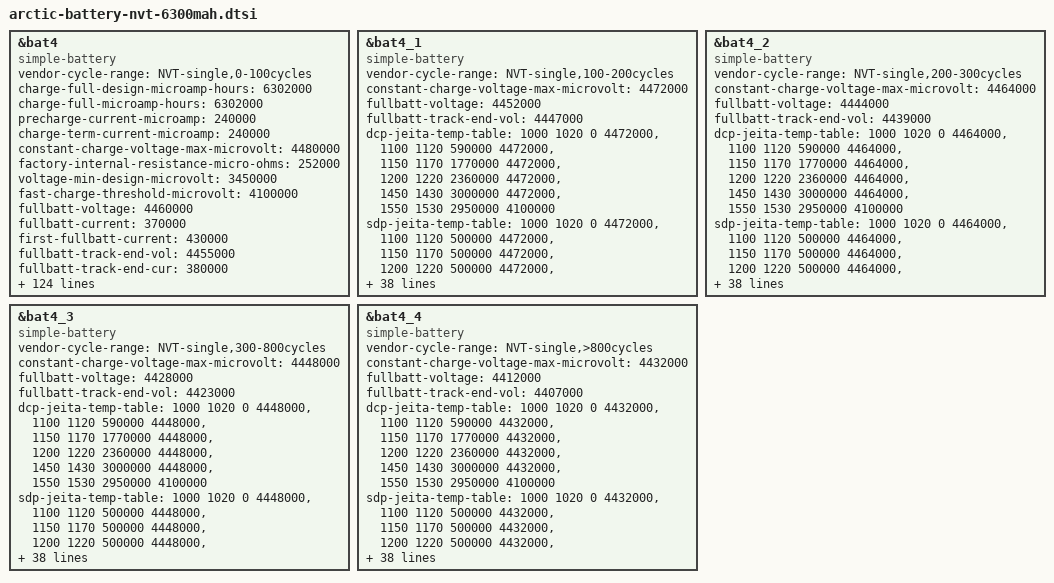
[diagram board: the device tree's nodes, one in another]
/* NVT-single aging 0--100 */
&bat4 {
	compatible = "simple-battery";
	status = "okay";
	vendor-cycle-range = "NVT-single,0-100cycles";
	charge-full-design-microamp-hours = <6302000>;
	charge-full-microamp-hours = <6302000>;
	precharge-current-microamp = <240000>;
	charge-term-current-microamp = <240000>;
	constant-charge-voltage-max-microvolt = <4480000>;
	factory-internal-resistance-micro-ohms = <252000>;
	voltage-min-design-microvolt = <3450000>;

	fast-charge-threshold-microvolt = <4100000>;
	fullbatt-voltage = <4460000>;
	fullbatt-current = <370000>;
	first-fullbatt-current = <430000>;
	fullbatt-track-end-vol = <4455000>;
	fullbatt-track-end-cur = <380000>;
	first-calib-voltage = <3580000>;
	first-calib-capacity = <50>;
	batt-ovp-threshold-microvolt = <4750000>;
	shutdown-voltage = <3150000>; //软件UVLO关机电压

	voltage-temp-table = <1119814 800>, <1007626 850>, <897107 900>,
				<791150 950>, <692012 1000>, <601214 1050>,
				<519546 1100>, <447188 1150>, <383853 1200>,
				<328947 1250>, <281696 1300>, <241249 1350>,
				<206756 1400>, <177412 1450>, <152480 1500>,
				<131307 1550>, <113324 1600>, <98032 1650>;

	temp-advance-fullcap-table = <50 100>, <25 100>, <10 100>, <0 100>,
		<(-10) 100>, <(-20) 100>;

	bcl-vbat-thres-celsius = <(-10)>, <0>, <10>, <25>, <45>;
	bcl-vbat-h-thres-0 = <3500>, <3400>;
	bcl-vbat-l-thres-0 = <3300>, <3200>;
	bcl-vbat-h-thres-1 = <3500>, <3400>;
	bcl-vbat-l-thres-1 = <3300>, <3200>;
	bcl-vbat-h-thres-2 = <3500>, <3400>;
	bcl-vbat-l-thres-2 = <3300>, <3200>;
	bcl-vbat-h-thres-3 = <3500>, <3400>;
	bcl-vbat-l-thres-3 = <3300>, <3200>;
	bcl-vbat-h-thres-4 = <3500>, <3400>;
	bcl-vbat-l-thres-4 = <3300>, <3200>;

	charge-sdp-current-microamp = <500000 500000>;
	charge-dcp-current-microamp = <2940000 1500000>;
	charge-cdp-current-microamp = <900000 900000>;
	charge-unknown-current-microamp = <1000000 1000000>;
	charge-fchg-current-microamp = <3000000 2000000>;
	charge-flash-current-microamp = <4900000 2700000>;
	charge-wl-bpp-current-microamp = <1000000 1000000>;
	charge-wl-epp-current-microamp = <2000000 1000000>;

	cap-calib-energy-density-ocv-table = <3400000 3690000>, <3895000 4480000>;

	dcp-jeita-temp-table = <1000 1020 0 4480000>, <1100 1120 590000 4480000>,
		<1150 1170 1770000 4480000>, <1200 1220 2360000 4480000>,
		<1450 1430 3000000 4480000>, <1550 1530 2950000 4100000>;
	sdp-jeita-temp-table = <1000 1020 0 4480000>, <1100 1120 500000 4480000>,
		<1150 1170 500000 4480000>, <1200 1220 500000 4480000>,
		<1450 1430 500000 4480000>, <1550 1530 500000 4100000>;
	cdp-jeita-temp-table = <1000 1020 0 4480000>, <1100 1120 590000 4480000>,
		<1150 1170 900000 4480000>, <1200 1220 900000 4480000>,
		<1450 1430 900000 4480000>, <1550 1530 900000 4100000>;
	unknown-jeita-temp-table = <1000 1020 0 4480000>, <1100 1120 590000 4480000>,
		<1150 1170 1000000 4480000>, <1200 1220 1000000 4480000>,
		<1450 1430 1000000 4480000>, <1550 1530 1000000 4100000>;
	fchg-jeita-temp-table = <1000 1020 0 4480000>, <1100 1120 590000 4480000>,
		<1150 1170 1770000 4480000>, <1200 1220 2360000 4480000>,
		<1450 1430 3000000 4480000>, <1550 1530 2950000 4100000>;
	flash-jeita-temp-table = <1000 1020 0 4480000>, <1100 1120 590000 4480000>,
		<1150 1170 1770000 4480000>, <1200 1220 2360000 4480000>,
		<1450 1430 3000000 4480000>, <1550 1530 2950000 4100000>;
	wl-bpp-jeita-temp-table = <1000 1020 0 4480000>, <1100 1120 500000 4480000>,
		<1150 1170 500000 4480000>, <1200 1220 500000 4480000>,
		<1450 1430 1000000 4480000>, <1550 1530 500000 4100000>;
	wl-epp-jeita-temp-table = <1000 1020 0 4480000>, <1100 1120 500000 4480000>,
		<1150 1170 500000 4480000>, <1200 1220 500000 4480000>,
		<1450 1430 2000000 4480000>, <1550 1530 500000 4100000>;


	bat-temp = <(-20)>, <(-10)>, <0>, <10>, <25>, <45>;

	/* temp-fcc */
	temp-fcc-fcc = <5744000>, <5938000>, <6229000>, <6271000>, <6302000>, <6250000>;

	/* temp-hc */
	temp-hc-hc = <20>, <20>, <20>, <10>, <10>, <10>;
	/* temp-zero-point-voltage */
	temp-zpvol-zpvol = <3430000>, <3430000>, <3430000>, <3450000>, <3450000>, <3450000>;
	/* temp-abs-zero-point-voltage */
	temp-abs-zpvol-zpvol = <3425000>, <3425000>, <3425000>, <3445000>, <3445000>, <3445000>;
	/* temp-bat-voltage */
	temp-batvol-batvol = <3570000>, <3570000>, <3570000>, <3580000>, <3580000>, <3580000>;

	/* cap-temp-ocv */
	cap-temp-ocv-cap = <100>, <99>, <98>, <97>, <96>, <95>, <94>, <93>, <92>, <91>, <90>,
			<89>, <88>, <87>, <86>, <85>, <84>, <83>, <82>, <81>, <80>,
			<79>, <78>, <77>, <76>, <75>, <74>, <73>, <72>, <71>, <70>,
			<69>, <68>, <67>, <66>, <65>, <64>, <63>, <62>, <61>, <60>,
			<59>, <58>, <57>, <56>, <55>, <54>, <53>, <52>, <51>, <50>,
			<49>, <48>, <47>, <46>, <45>, <44>, <43>, <42>, <41>, <40>,
			<39>, <38>, <37>, <36>, <35>, <34>, <33>, <32>, <31>, <30>,
			<29>, <28>, <27>, <26>, <25>, <24>, <23>, <22>, <21>, <20>,
			<19>, <18>, <17>, <16>, <15>, <14>, <13>, <12>, <11>, <10>,
			<9>, <8>, <7>, <6>, <5>, <4>, <3>, <2>, <1>, <0>;
	cap-temp-ocv-ocv = <
			/* -20 celsius */
			4431000 4394000 4370000 4350000 4333000 4318000 4302000 4288000 4275000 4262000
			4248000 4236000 4224000 4211000 4199000 4188000 4176000 4166000 4156000 4145000
			4135000 4125000 4116000 4106000 4097000 4088000 4078000 4070000 4060000 4051000
			4042000 4033000 4024000 4015000 4006000 3997000 3988000 3979000 3970000 3960000
			3952000 3943000 3934000 3926000 3917000 3908000 3900000 3892000 3884000 3877000
			3870000 3862000 3856000 3850000 3844000 3838000 3832000 3827000 3822000 3818000
			3813000 3809000 3806000 3802000 3799000 3796000 3794000 3792000 3789000 3787000
			3785000 3783000 3780000 3778000 3776000 3774000 3770000 3768000 3765000 3762000
			3759000 3755000 3752000 3748000 3742000 3738000 3732000 3725000 3717000 3708000
			3698000 3686000 3672000 3660000 3646000 3630000 3612000 3590000 3570000 3551000
			3532000
			/* -10 celsius */
			4431000 4398000 4374000 4356000 4340000 4325000 4311000 4297000 4283000 4270000
			4256000 4244000 4232000 4219000 4208000 4196000 4186000 4174000 4164000 4154000
			4144000 4134000 4125000 4116000 4106000 4096000 4086000 4078000 4068000 4058000
			4049000 4040000 4030000 4021000 4012000 4002000 3994000 3984000 3976000 3966000
			3958000 3948000 3940000 3930000 3921000 3912000 3902000 3893000 3884000 3876000
			3868000 3861000 3854000 3847000 3841000 3835000 3830000 3825000 3820000 3816000
			3811000 3807000 3804000 3800000 3797000 3794000 3791000 3789000 3787000 3785000
			3784000 3782000 3780000 3779000 3777000 3775000 3773000 3772000 3769000 3767000
			3764000 3761000 3757000 3754000 3748000 3744000 3736000 3728000 3718000 3706000
			3690000 3670000 3646000 3623000 3602000 3582000 3562000 3544000 3530000 3516000
			3501000
			/* 0 celsius */
			4432000 4400000 4376000 4358000 4341000 4326000 4312000 4298000 4284000 4272000
			4260000 4248000 4236000 4224000 4214000 4202000 4192000 4182000 4171000 4160000
			4150000 4140000 4129000 4118000 4108000 4098000 4086000 4076000 4066000 4056000
			4046000 4036000 4026000 4017000 4008000 3998000 3990000 3981000 3972000 3964000
			3956000 3947000 3938000 3930000 3920000 3909000 3898000 3886000 3875000 3866000
			3857000 3850000 3844000 3837000 3832000 3827000 3822000 3818000 3813000 3809000
			3806000 3802000 3798000 3796000 3793000 3790000 3788000 3786000 3784000 3783000
			3782000 3780000 3780000 3778000 3777000 3776000 3774000 3772000 3770000 3766000
			3762000 3758000 3754000 3748000 3741000 3733000 3722000 3706000 3685000 3660000
			3632000 3606000 3581000 3562000 3545000 3530000 3516000 3502000 3484000 3455000
			3400000
			/* 10 celsius */
			4438000 4408000 4384000 4364000 4348000 4332000 4318000 4305000 4292000 4279000
			4266000 4254000 4242000 4231000 4220000 4208000 4198000 4186000 4176000 4165000
			4154000 4143000 4132000 4121000 4110000 4100000 4089000 4078000 4068000 4058000
			4048000 4038000 4028000 4018000 4010000 4000000 3992000 3982000 3974000 3966000
			3958000 3949000 3940000 3932000 3924000 3914000 3904000 3892000 3879000 3868000
			3859000 3852000 3845000 3840000 3834000 3828000 3824000 3820000 3816000 3812000
			3808000 3804000 3801000 3798000 3795000 3792000 3790000 3788000 3786000 3784000
			3783000 3782000 3781000 3780000 3779000 3777000 3776000 3774000 3770000 3767000
			3763000 3758000 3754000 3750000 3746000 3740000 3732000 3722000 3710000 3695000
			3676000 3648000 3620000 3596000 3576000 3559000 3543000 3526000 3503000 3462000
			3400000
			/* 25 celsius */
			4438000 4406000 4381000 4361000 4344000 4329000 4315000 4302000 4289000 4276000
			4264000 4252000 4240000 4229000 4218000 4207000 4196000 4185000 4174000 4163000
			4152000 4141000 4130000 4119000 4108000 4098000 4087000 4076000 4066000 4056000
			4046000 4036000 4026000 4017000 4008000 3999000 3990000 3981000 3973000 3965000
			3957000 3949000 3942000 3933000 3926000 3917000 3907000 3894000 3880000 3868000
			3860000 3853000 3846000 3841000 3836000 3831000 3826000 3822000 3818000 3814000
			3810000 3807000 3804000 3801000 3798000 3796000 3793000 3791000 3789000 3788000
			3786000 3785000 3783000 3782000 3780000 3776000 3773000 3770000 3766000 3762000
			3758000 3755000 3752000 3748000 3745000 3740000 3733000 3726000 3720000 3712000
			3702000 3692000 3683000 3666000 3642000 3614000 3590000 3567000 3530000 3474000
			3400000
			/* 45 celsius */
			4425000 4395000 4372000 4353000 4336000 4321000 4307000 4294000 4280000 4268000
			4256000 4244000 4234000 4222000 4211000 4200000 4190000 4178000 4168000 4156000
			4146000 4134000 4124000 4113000 4102000 4092000 4081000 4071000 4060000 4050000
			4040000 4031000 4021000 4012000 4002000 3994000 3985000 3977000 3968000 3960000
			3952000 3945000 3937000 3930000 3922000 3914000 3904000 3890000 3876000 3865000
			3858000 3852000 3846000 3840000 3835000 3830000 3826000 3821000 3817000 3813000
			3809000 3806000 3802000 3799000 3796000 3794000 3791000 3789000 3786000 3785000
			3783000 3782000 3779000 3777000 3772000 3766000 3760000 3756000 3754000 3750000
			3746000 3742000 3738000 3735000 3732000 3726000 3720000 3714000 3707000 3700000
			3690000 3683000 3677000 3666000 3647000 3622000 3598000 3572000 3531000 3472000
			3400000
			>;


	/* cap-temp-resist */
	cap-temp-resist-cap = <100>, <99>, <98>, <97>, <96>, <95>, <94>, <93>, <92>, <91>, <90>,
			<89>, <88>, <87>, <86>, <85>, <84>, <83>, <82>, <81>, <80>,
			<79>, <78>, <77>, <76>, <75>, <74>, <73>, <72>, <71>, <70>,
			<69>, <68>, <67>, <66>, <65>, <64>, <63>, <62>, <61>, <60>,
			<59>, <58>, <57>, <56>, <55>, <54>, <53>, <52>, <51>, <50>,
			<49>, <48>, <47>, <46>, <45>, <44>, <43>, <42>, <41>, <40>,
			<39>, <38>, <37>, <36>, <35>, <34>, <33>, <32>, <31>, <30>,
			<29>, <28>, <27>, <26>, <25>, <24>, <23>, <22>, <21>, <20>,
			<19>, <18>, <17>, <16>, <15>, <14>, <13>, <12>, <11>, <10>,
			<9>, <8>, <7>, <6>, <5>, <4>, <3>, <2>, <1>, <0>;
	cap-temp-resist-resist = <
		  /* -20 celsius m o */
			790  790  785  781  777  773  770  764  758  751
			747  744  741  739  734  730  728  720  720  716
			715  709  708  708  704  704  708  706  704  703
			702  704  704  703  704  702  700  702  700  700
			700  702  697  697  700  693  690  691  694  695
			694  692  692  696  700  700  700  704  704  706
			712  716  720  720  726  733  742  751  757  766
			776  784  798  810  826  846  863  884  906  926
			951  978 1005 1040 1083 1130 1182 1241 1325 1442
			1600 1832 2178 2645 2871 2871 2871 2871 2871 2871
			2871
		  /* -10 celsius */
			394  394  402  402  404  406  406  404  403  401
			398  397  395  394  392  390  390  389  389  388
			388  388  390  390  390  390  392  392  392  393
			394  394  396  394  396  396  396  396  397  396
			396  394  394  392  390  386  384  380  378  375
			372  370  368  368  369  370  370  372  373  374
			375  377  379  380  382  384  386  389  392  396
			402  406  412  418  426  433  444  454  466  480
			494  512  531  554  583  616  656  707  770  849
			953 1112 1410 2107 2760 2760 2760 2760 2760 2760
			2760
		  /* 0 celsius */
			196  196  195  193  192  192  190  190  190  190
			190  189  188  190  190  190  190  190  190  190
			190  190  190  190  190  192  192  193  194  194
			196  196  198  199  201  202  204  206  207  209
			210  211  212  212  210  205  200  193  187  182
			178  176  176  174  176  176  176  174  176  176
			178  176  177  178  180  180  181  182  184  184
			184  187  190  192  194  196  198  200  203  206
			209  213  220  228  241  263  295  338  376  400
			416  436  473  566  878 1946 2548 2548 2548 2548
			2548
		  /* 10 celsius */
			136  136  135  134  133  132  132  132  133  134
			134  134  134  134  134  134  135  134  135  134
			136  135  136  136  136  136  138  138  138  140
			140  140  142  143  144  146  147  148  150  152
			154  156  158  160  160  160  156  150  140  134
			132  130  130  129  129  128  128  129  130  130
			129  130  130  131  132  132  132  133  134  134
			134  136  136  136  138  138  139  139  140  139
			138  138  140  142  147  151  156  166  182  209
			240  261  266  266  272  288  322  396  647 1580
			2262
		  /* 25 celsius */
			98  98 100  98  99  98  98  98  98  99
			99  99 100 100 100 100 100 100 100 100
			100 100 100 100 101 101 102 102 102 102
			102 104 104 106 106 106 108 108 110 112
			114 114 116 118 120 122 120 115 106 100
			98  98  97  97  96  97  97  96  98  97
			98  98  98 100  98  99 100 100 102 102
			103 104 104 104 104 102  99  99  99  99
			98  98  99 100 102 102 102 102 102 104
			106 110 116 126 137 142 142 142 141 142
			150
		  /* 45 celsius */
			87  87  89  89  90  90  90  90  90  90
			90  90  90  90  90  91  90  91  92  91
			92  91  92  92  92  92  92  92  92  93
			92  94  93  94  95  94  95  96  97  98
			99 100 102 102 104 107 106  98  92  91
			91  90  90  90  90  90  90  90  90  90
			90  90  91  90  92  92  92  92  93  94
			95  96  98  98  94  90  89  91  92  92
			91  92  92  93  94  94  94  93  94  95
			94  96 100 102 104 108 110 109 108 109
			112
		>;
	cap-temp-resist-cycle = <300>, <600>;
	cap-temp-resist-ratio-0 = <
		  /* -20 celsius m o */
		  1030 1030 1030 1030 1030 1030 1030 1030 1030 1030 1040
		  1050 1050 1050 1060 1060 1060 1060 1060 1060 1060 1060
		  1060 1060 1060 1060 1060 1060 1060 1060 1060 1060 1060
		  1060 1060 1060 1060 1060 1060 1060 1060 1060 1060 1060
		  1060 1060 1060 1060 1060 1060 1060 1060 1060 1060 1060
		  1060 1060 1060 1060 1060 1060 1060 1060 1060 1050 1050
		  1050 1050 1050 1050 1050 1050 1050 1050 1050 1050 1050
		  1050 1050 1050 1050 1050 1050 1050 1050 1050 1050 1050
		  1050 1050 1050 1050 1050 1050 1050 1050 1050 1050 1050
		  1050 1050
		  /* -10 celsius */
		  1050 1050 1050 1050 1050 1050 1050 1050 1050 1050 1050
		  1050 1050 1050 1050 1050 1050 1050 1050 1050 1050 1050
		  1050 1050 1050 1050 1050 1050 1050 1050 1050 1050 1050
		  1050 1050 1050 1050 1050 1050 1050 1050 1050 1050 1050
		  1050 1050 1050 1050 1050 1050 1050 1050 1050 1050 1050
		  1050 1050 1050 1050 1050 1050 1050 1050 1050 1050 1050
		  1050 1050 1050 1050 1050 1050 1050 1050 1050 1050 1050
		  1050 1050 1050 1050 1050 1050 1050 1050 1050 1050 1050
		  1050 1050 1050 1050 1050 1050 1050 1050 1050 1050 1050
		  1050 1050
		  /* 0 celsius */
		  1160 1160 1160 1160 1160 1160 1160 1160 1170 1170 1170
		  1170 1170 1170 1170 1170 1170 1170 1170 1170 1170 1170
		  1170 1170 1170 1170 1170 1170 1170 1170 1170 1170 1170
		  1170 1170 1170 1180 1180 1180 1180 1180 1180 1180 1180
		  1180 1180 1190 1190 1190 1190 1190 1190 1190 1190 1190
		  1190 1190 1190 1190 1190 1190 1190 1190 1190 1190 1190
		  1190 1200 1200 1210 1220 1220 1220 1220 1220 1220 1230
		  1230 1230 1230 1230 1230 1230 1230 1230 1230 1230 1230
		  1230 1230 1230 1230 1250 1270 1290 1320 1350 1370 1400
		  1430 1430
		  /* 10 celsius */
		  1270 1270 1270 1270 1270 1270 1270 1270 1270 1280 1280
		  1280 1280 1290 1290 1290 1290 1290 1290 1290 1290 1290
		  1290 1300 1300 1300 1300 1300 1300 1300 1300 1300 1300
		  1300 1310 1310 1310 1310 1310 1310 1310 1310 1310 1310
		  1320 1320 1320 1320 1320 1320 1320 1320 1320 1320 1320
		  1320 1320 1330 1330 1330 1330 1330 1330 1330 1330 1330
		  1330 1330 1330 1330 1340 1340 1340 1340 1340 1340 1350
		  1360 1380 1400 1410 1430 1450 1470 1490 1500 1510 1520
		  1530 1530 1530 1530 1530 1530 1530 1530 1530 1530 1530
		  1530 1530
		  /* 25 celsius */
		  1110 1110 1110 1110 1110 1110 1110 1120 1120 1120 1130
		  1130 1140 1140 1140 1140 1140 1130 1130 1130 1130 1130
		  1130 1120 1120 1120 1120 1120 1120 1120 1120 1120 1120
		  1130 1130 1130 1130 1130 1140 1140 1140 1140 1140 1150
		  1150 1160 1160 1160 1160 1160 1160 1160 1160 1150 1150
		  1150 1150 1150 1160 1160 1160 1160 1160 1160 1150 1150
		  1150 1150 1150 1160 1160 1160 1160 1160 1160 1160 1160
		  1160 1160 1160 1160 1160 1160 1160 1160 1160 1150 1150
		  1150 1150 1150 1150 1150 1160 1160 1160 1160 1160 1160
		  1160 1160
		  /* 45 celsius */
		  1260 1260 1260 1260 1260 1260 1260 1270 1280 1290 1300
		  1300 1300 1300 1300 1300 1300 1300 1300 1300 1300 1300
		  1290 1290 1280 1270 1280 1290 1300 1310 1310 1310 1310
		  1310 1310 1310 1310 1310 1310 1310 1310 1310 1300 1290
		  1280 1270 1270 1270 1270 1270 1290 1290 1290 1290 1300
		  1310 1310 1310 1310 1310 1310 1310 1310 1300 1290 1290
		  1290 1290 1290 1300 1310 1310 1320 1320 1320 1320 1320
		  1320 1320 1320 1320 1320 1320 1320 1320 1320 1320 1310
		  1310 1310 1310 1310 1310 1310 1310 1320 1320 1320 1320
		  1320 1320
		>;

	cap-temp-resist-ratio-1 = <
		  /* -20 celsius m o */
		  1160 1160 1160 1160 1160 1160 1160 1160 1160 1170 1170
		  1180 1180 1190 1190 1190 1190 1200 1200 1210 1210 1210
		  1220 1220 1230 1230 1240 1250 1260 1270 1270 1270 1280
		  1290 1300 1310 1320 1340 1360 1380 1400 1400 1430 1460
		  1490 1520 1520 1520 1550 1590 1630 1660 1660 1690 1720
		  1750 1770 1770 1770 1770 1770 1770 1770 1770 1770 1770
		  1770 1770 1770 1770 1770 1770 1770 1770 1770 1770 1770
		  1770 1770 1770 1770 1770 1770 1770 1770 1770 1770 1770
		  1770 1770 1770 1770 1770 1770 1770 1770 1770 1770 1770
		  1770 1770
		  /* -10 celsius */
		  1180 1180 1180 1180 1180 1180 1180 1180 1170 1170 1170
		  1170 1170 1170 1170 1170 1170 1170 1170 1170 1170 1170
		  1170 1170 1170 1170 1170 1170 1170 1170 1170 1170 1170
		  1170 1170 1170 1170 1170 1170 1170 1170 1170 1170 1190
		  1190 1190 1190 1190 1200 1200 1200 1200 1200 1210 1210
		  1210 1210 1210 1210 1220 1240 1250 1270 1290 1290 1290
		  1290 1290 1290 1290 1300 1310 1320 1330 1340 1350 1350
		  1350 1370 1390 1410 1420 1440 1440 1460 1480 1500 1530
		  1550 1570 1590 1610 1620 1620 1620 1620 1620 1620 1620
		  1620 1620
		  /* 0 celsius */
		  1420 1420 1420 1420 1420 1420 1420 1420 1410 1410 1410
		  1410 1410 1410 1410 1410 1410 1410 1410 1410 1410 1410
		  1400 1400 1400 1400 1400 1400 1400 1400 1400 1400 1400
		  1400 1400 1400 1400 1400 1400 1400 1400 1400 1410 1410
		  1410 1410 1420 1420 1420 1420 1420 1420 1420 1420 1420
		  1420 1430 1430 1430 1430 1430 1430 1450 1450 1450 1450
		  1450 1450 1500 1500 1500 1500 1500 1500 1530 1530 1530
		  1530 1530 1530 1550 1550 1550 1550 1610 1610 1610 1610
		  1650 1700 1750 1800 1850 1900 1900 1900 1900 1900 1900
		  1900 1900
		  /* 10 celsius */
		  1400 1400 1400 1400 1400 1400 1400 1400 1400 1420 1420
		  1420 1420 1420 1420 1420 1420 1420 1420 1420 1420 1420
		  1420 1420 1420 1420 1420 1420 1410 1410 1410 1410 1410
		  1410 1410 1410 1410 1410 1410 1410 1410 1410 1410 1410
		  1410 1420 1420 1420 1420 1430 1430 1430 1430 1430 1420
		  1430 1430 1430 1430 1430 1430 1430 1430 1430 1430 1430
		  1430 1430 1430 1430 1470 1470 1470 1470 1470 1530 1530
		  1530 1530 1530 1590 1590 1590 1590 1630 1680 1710 1710
		  1780 1840 1900 1950 2000 2050 2100 2150 2200 2250 2250
		  2250 2250
		  /* 25 celsius */
		  1320 1320 1320 1320 1320 1320 1320 1320 1320 1320 1320
		  1320 1310 1310 1310 1310 1310 1310 1300 1300 1300 1300
		  1300 1290 1290 1290 1290 1290 1280 1280 1280 1280 1280
		  1280 1280 1280 1280 1280 1280 1280 1280 1280 1280 1290
		  1290 1300 1310 1310 1310 1310 1310 1310 1310 1310 1310
		  1310 1310 1310 1310 1310 1310 1310 1310 1310 1310 1310
		  1310 1310 1310 1310 1310 1310 1310 1320 1330 1340 1350
		  1350 1360 1360 1360 1360 1360 1370 1370 1370 1380 1390
		  1400 1410 1420 1430 1450 1460 1460 1460 1460 1460 1460
		  1460 1460
		  /* 45 celsius */
		  1298 1298 1298 1298 1298 1298 1298 1308 1318 1329 1339
		  1339 1339 1339 1339 1339 1339 1339 1339 1339 1339 1339
		  1329 1329 1318 1308 1318 1329 1339 1349 1349 1349 1349
		  1349 1349 1349 1349 1349 1349 1349 1349 1349 1339 1329
		  1318 1308 1308 1308 1308 1308 1329 1329 1329 1329 1339
		  1349 1349 1349 1349 1349 1349 1349 1349 1339 1329 1329
		  1329 1329 1329 1339 1349 1349 1360 1360 1360 1360 1360
		  1360 1360 1360 1360 1360 1360 1360 1360 1360 1360 1349
		  1349 1349 1349 1349 1349 1349 1349 1360 1360 1360 1360
		  1360 1360
		>;
};

/* NVT-single aging 100--200 */
&bat4_1 {
	compatible = "simple-battery";
	status = "okay";
	vendor-cycle-range = "NVT-single,100-200cycles";
	constant-charge-voltage-max-microvolt = <4472000>;
	fullbatt-voltage = <4452000>;
	fullbatt-track-end-vol = <4447000>;

	dcp-jeita-temp-table = <1000 1020 0 4472000>, <1100 1120 590000 4472000>,
		<1150 1170 1770000 4472000>, <1200 1220 2360000 4472000>,
		<1450 1430 3000000 4472000>, <1550 1530 2950000 4100000>;
	sdp-jeita-temp-table = <1000 1020 0 4472000>, <1100 1120 500000 4472000>,
		<1150 1170 500000 4472000>, <1200 1220 500000 4472000>,
		<1450 1430 500000 4472000>, <1550 1530 500000 4100000>;
	cdp-jeita-temp-table = <1000 1020 0 4472000>, <1100 1120 590000 4472000>,
		<1150 1170 900000 4472000>, <1200 1220 900000 4472000>,
		<1450 1430 900000 4472000>, <1550 1530 900000 4100000>;
	unknown-jeita-temp-table = <1000 1020 0 4472000>, <1100 1120 590000 4472000>,
		<1150 1170 1000000 4472000>, <1200 1220 1000000 4472000>,
		<1450 1430 1000000 4472000>, <1550 1530 1000000 4100000>;
	fchg-jeita-temp-table = <1000 1020 0 4472000>, <1100 1120 590000 4472000>,
		<1150 1170 1770000 4472000>, <1200 1220 2360000 4472000>,
		<1450 1430 3000000 4472000>, <1550 1530 2950000 4100000>;
	flash-jeita-temp-table = <1000 1020 0 4472000>, <1100 1120 590000 4472000>,
		<1150 1170 1770000 4472000>, <1200 1220 2360000 4472000>,
		<1450 1430 3000000 4472000>, <1550 1530 2950000 4100000>;
	wl-bpp-jeita-temp-table = <1000 1020 0 4472000>, <1100 1120 500000 4472000>,
		<1150 1170 500000 4472000>, <1200 1220 500000 4472000>,
		<1450 1430 1000000 4472000>, <1550 1530 500000 4100000>;
	wl-epp-jeita-temp-table = <1000 1020 0 4472000>, <1100 1120 500000 4472000>,
		<1150 1170 500000 4472000>, <1200 1220 500000 4472000>,
		<1450 1430 2000000 4472000>, <1550 1530 500000 4100000>;
};

/* NVT-single aging 200--300 */
&bat4_2 {
	compatible = "simple-battery";
	status = "okay";
	vendor-cycle-range = "NVT-single,200-300cycles";
	constant-charge-voltage-max-microvolt = <4464000>;
	fullbatt-voltage = <4444000>;
	fullbatt-track-end-vol = <4439000>;

	dcp-jeita-temp-table = <1000 1020 0 4464000>, <1100 1120 590000 4464000>,
		<1150 1170 1770000 4464000>, <1200 1220 2360000 4464000>,
		<1450 1430 3000000 4464000>, <1550 1530 2950000 4100000>;
	sdp-jeita-temp-table = <1000 1020 0 4464000>, <1100 1120 500000 4464000>,
		<1150 1170 500000 4464000>, <1200 1220 500000 4464000>,
		<1450 1430 500000 4464000>, <1550 1530 500000 4100000>;
	cdp-jeita-temp-table = <1000 1020 0 4464000>, <1100 1120 590000 4464000>,
		<1150 1170 900000 4464000>, <1200 1220 900000 4464000>,
		<1450 1430 900000 4464000>, <1550 1530 900000 4100000>;
	unknown-jeita-temp-table = <1000 1020 0 4464000>, <1100 1120 590000 4464000>,
		<1150 1170 1000000 4464000>, <1200 1220 1000000 4464000>,
		<1450 1430 1000000 4464000>, <1550 1530 1000000 4100000>;
	fchg-jeita-temp-table = <1000 1020 0 4464000>, <1100 1120 590000 4464000>,
		<1150 1170 1770000 4464000>, <1200 1220 2360000 4464000>,
		<1450 1430 3000000 4464000>, <1550 1530 2950000 4100000>;
	flash-jeita-temp-table = <1000 1020 0 4464000>, <1100 1120 590000 4464000>,
		<1150 1170 1770000 4464000>, <1200 1220 2360000 4464000>,
		<1450 1430 3000000 4464000>, <1550 1530 2950000 4100000>;
	wl-bpp-jeita-temp-table = <1000 1020 0 4464000>, <1100 1120 500000 4464000>,
		<1150 1170 500000 4464000>, <1200 1220 500000 4464000>,
		<1450 1430 1000000 4464000>, <1550 1530 500000 4100000>;
	wl-epp-jeita-temp-table = <1000 1020 0 4464000>, <1100 1120 500000 4464000>,
		<1150 1170 500000 4464000>, <1200 1220 500000 4464000>,
		<1450 1430 2000000 4464000>, <1550 1530 500000 4100000>;
};

/* NVT-single aging 300--800 */
&bat4_3 {
	compatible = "simple-battery";
	status = "okay";
	vendor-cycle-range = "NVT-single,300-800cycles";
	constant-charge-voltage-max-microvolt = <4448000>;
	fullbatt-voltage = <4428000>;
	fullbatt-track-end-vol = <4423000>;

	dcp-jeita-temp-table = <1000 1020 0 4448000>, <1100 1120 590000 4448000>,
		<1150 1170 1770000 4448000>, <1200 1220 2360000 4448000>,
		<1450 1430 3000000 4448000>, <1550 1530 2950000 4100000>;
	sdp-jeita-temp-table = <1000 1020 0 4448000>, <1100 1120 500000 4448000>,
		<1150 1170 500000 4448000>, <1200 1220 500000 4448000>,
		<1450 1430 500000 4448000>, <1550 1530 500000 4100000>;
	cdp-jeita-temp-table = <1000 1020 0 4448000>, <1100 1120 590000 4448000>,
		<1150 1170 900000 4448000>, <1200 1220 900000 4448000>,
		<1450 1430 900000 4448000>, <1550 1530 900000 4100000>;
	unknown-jeita-temp-table = <1000 1020 0 4448000>, <1100 1120 590000 4448000>,
		<1150 1170 1000000 4448000>, <1200 1220 1000000 4448000>,
		<1450 1430 1000000 4448000>, <1550 1530 1000000 4100000>;
	fchg-jeita-temp-table = <1000 1020 0 4448000>, <1100 1120 590000 4448000>,
		<1150 1170 1770000 4448000>, <1200 1220 2360000 4448000>,
		<1450 1430 3000000 4448000>, <1550 1530 2950000 4100000>;
	flash-jeita-temp-table = <1000 1020 0 4448000>, <1100 1120 590000 4448000>,
		<1150 1170 1770000 4448000>, <1200 1220 2360000 4448000>,
		<1450 1430 3000000 4448000>, <1550 1530 2950000 4100000>;
	wl-bpp-jeita-temp-table = <1000 1020 0 4448000>, <1100 1120 500000 4448000>,
		<1150 1170 500000 4448000>, <1200 1220 500000 4448000>,
		<1450 1430 1000000 4448000>, <1550 1530 500000 4100000>;
	wl-epp-jeita-temp-table = <1000 1020 0 4448000>, <1100 1120 500000 4448000>,
		<1150 1170 500000 4448000>, <1200 1220 500000 4448000>,
		<1450 1430 2000000 4448000>, <1550 1530 500000 4100000>;
};

/* NVT-single aging > 800 */
&bat4_4 {
	compatible = "simple-battery";
	status = "okay";
	vendor-cycle-range = "NVT-single,>800cycles";
	constant-charge-voltage-max-microvolt = <4432000>;
	fullbatt-voltage = <4412000>;
	fullbatt-track-end-vol = <4407000>;

	dcp-jeita-temp-table = <1000 1020 0 4432000>, <1100 1120 590000 4432000>,
		<1150 1170 1770000 4432000>, <1200 1220 2360000 4432000>,
		<1450 1430 3000000 4432000>, <1550 1530 2950000 4100000>;
	sdp-jeita-temp-table = <1000 1020 0 4432000>, <1100 1120 500000 4432000>,
		<1150 1170 500000 4432000>, <1200 1220 500000 4432000>,
		<1450 1430 500000 4432000>, <1550 1530 500000 4100000>;
	cdp-jeita-temp-table = <1000 1020 0 4432000>, <1100 1120 590000 4432000>,
		<1150 1170 900000 4432000>, <1200 1220 900000 4432000>,
		<1450 1430 900000 4432000>, <1550 1530 900000 4100000>;
	unknown-jeita-temp-table = <1000 1020 0 4432000>, <1100 1120 590000 4432000>,
		<1150 1170 1000000 4432000>, <1200 1220 1000000 4432000>,
		<1450 1430 1000000 4432000>, <1550 1530 1000000 4100000>;
	fchg-jeita-temp-table = <1000 1020 0 4432000>, <1100 1120 590000 4432000>,
		<1150 1170 1770000 4432000>, <1200 1220 2360000 4432000>,
		<1450 1430 3000000 4432000>, <1550 1530 2950000 4100000>;
	flash-jeita-temp-table = <1000 1020 0 4432000>, <1100 1120 590000 4432000>,
		<1150 1170 1770000 4432000>, <1200 1220 2360000 4432000>,
		<1450 1430 3000000 4432000>, <1550 1530 2950000 4100000>;
	wl-bpp-jeita-temp-table = <1000 1020 0 4432000>, <1100 1120 500000 4432000>,
		<1150 1170 500000 4432000>, <1200 1220 500000 4432000>,
		<1450 1430 1000000 4432000>, <1550 1530 500000 4100000>;
	wl-epp-jeita-temp-table = <1000 1020 0 4432000>, <1100 1120 500000 4432000>,
		<1150 1170 500000 4432000>, <1200 1220 500000 4432000>,
		<1450 1430 2000000 4432000>, <1550 1530 500000 4100000>;
};
